# MCXN947_cm33_core0 register map
Vendor: nxp.com; File version: 1.0
CPU: CM33 r2p0, little endian, MPU, FPU, VTOR, 3 interrupt priority bits
Registers are 32-bit, read-write, reset 0x0 unless marked. A register's access mark holds for its fields unless they carry their own. Offsets are from the block's base; [hi:lo] are bit positions; {n}, {i} and the like mark numbered series; 'fields as' and 'values as' point back to an identical list.

## INPUTMUX0 (part 2 of 2) — INPUTMUX
Base 0x40006000
{0x580+4i} OPAMP{i}_TRIG reset 0x3F (i=0..2) — OPAMP{i} Trigger Input Connections
  [5:0] INP — OPAMP trigger input connections
    {v}=PINT PIN_INT{v} input is selected (v=0..3); {v}=SCT_OUT{v} input is selected (v=4..8); {v}=CTIMER{v-9}_MAT3 input is selected (v=9..13); 14=PINT GPIO_INT_BMAT input is selected; {v}=ADC0_tcomp[{v-15}] input is selected (v=15..18); {v}=ADC1_tcomp[{v-19}] input is selected (v=19..22); 23=PWM0_A0_TRIG0 input is selected; 24=PWM0_A0_TRIG1 input is selected; 25=PWM0_A1_TRIG0 input is selected; 26=PWM0_A1_TRIG1 input is selected; 27=PWM0_A2_TRIG0 input is selected; 28=PWM0_A2_TRIG1 input is selected; 29=PWM0_A3_TRIG0 input is selected; 30=PWM0_A3_TRIG1 input is selected; 31=PWM1_A0_TRIG0 input is selected; 32=PWM1_A0_TRIG1 input is selected; 33=PWM1_A1_TRIG0 input is selected; 34=PWM1_A1_TRIG1 input is selected; 35=PWM1_A2_TRIG0 input is selected; 36=PWM1_A2_TRIG1 input is selected; 37=PWM1_A3_TRIG0 input is selected; 38=PWM1_A3_TRIG1 input is selected; 39=EVTG_OUT0A input is selected; 40=EVTG_OUT0B input is selected; 41=EVTG_OUT1A input is selected; 42=EVTG_OUT1B input is selected; 43=EVTG_OUT2A input is selected; 44=EVTG_OUT2B input is selected; 45=EVTG_OUT3A input is selected; 46=EVTG_OUT3B input is selected; {v}=TRIG_IN{v-47} input is selected (v=47..50); {v}=FlexIO CH{v-47} input is selected (v=51..54)
0x5A0 FLEXCOMM0_TRIG reset 0x3F — LP_FLEXCOMM0 Trigger Input Connections
  [5:0] INP — FLEXCOMM0 trigger input connections
    0=PINT PIN_INT4 input is selected; 1=PINT PIN_INT5 input is selected; 2=PINT PIN_INT6 input is selected; 3=SCT_OUT5 input is selected; 4=SCT_OUT6 input is selected; 5=SCT_OUT7 input is selected; 6=CTIMER0_MAT1 input is selected; 7=CTIMER1_MAT1 input is selected; 8=CTIMER2_MAT0 input is selected; 9=CTIMER3_MAT0 input is selected; 10=CTIMER4_MAT0 input is selected; 11=LPTMR0 input is selected; 12=LPTMR1 input is selected; 13=ARM_TXEV input is selected; 14=PINT GPIO_INT_BMAT input is selected; 15=CMP0_OUT input is selected; 16=CMP1_OUT input is selected; 17=CMP2_OUT input is selected; 18=EVTG_OUT0A input is selected; 19=EVTG_OUT0B input is selected; 20=EVTG_OUT1A input is selected; 21=EVTG_OUT1B input is selected; 22=EVTG_OUT2A input is selected; 23=EVTG_OUT2B input is selected; 24=EVTG_OUT3A input is selected; 25=EVTG_OUT3B input is selected; {v}=TRIG_IN{v-26} input is selected (v=26..30); 31=TRIG_IN10 input is selected; 32=TRIG_IN11 input is selected; {v}=FlexIO CH{v-29} input is selected (v=33..36); 37=USB0 ipp_ind_uart_rxd_usbmux input is selected; 38=GPIO2 Pin Event Trig 0 input is selected; 39=GPIO2 Pin Event Trig 1 input is selected; 40=GPIO3 Pin Event Trig 0 input is selected; 41=GPIO3 Pin Event Trig 1 input is selected; 42=WUU input is selected
0x5C0 FLEXCOMM1_TRIG reset 0x3F — LP_FLEXCOMM1 Trigger Input Connections
  [5:0] INP — FLEXCOMM1 trigger input connections
    values as FLEXCOMM0_TRIG.INP
0x5E0 FLEXCOMM2_TRIG reset 0x3F — LP_FLEXCOMM2 Trigger Input Connections
  [5:0] INP — FLEXCOMM2 trigger input connections
    0=PINT PIN_INT4 input is selected; 1=PINT PIN_INT6 input is selected; 2=PINT PIN_INT7 input is selected; 3=SCT_OUT5 input is selected; 4=SCT_OUT8 input is selected; 5=SCT_OUT9 input is selected; {v}=CTIMER{v-6}_MAT1 input is selected (v=6..10); 11=LPTMR0 input is selected; 12=LPTMR1 input is selected; 13=ARM_TXEV input is selected; 14=PINT GPIO_INT_BMAT input is selected; 15=CMP0_OUT input is selected; 16=CMP1_OUT input is selected; 17=CMP2_OUT input is selected; 18=EVTG_OUT0A input is selected; 19=EVTG_OUT0B input is selected; 20=EVTG_OUT1A input is selected; 21=EVTG_OUT1B input is selected; 22=EVTG_OUT2A input is selected; 23=EVTG_OUT2B input is selected; 24=EVTG_OUT3A input is selected; 25=EVTG_OUT3B input is selected; {v}=TRIG_IN{v-26} input is selected (v=26..30); 31=TRIG_IN10 input is selected; 32=TRIG_IN11 input is selected; {v}=FlexIO CH{v-29} input is selected (v=33..36); 37=USB0 ipp_ind_uart_rxd_usbmux input is selected; 38=GPIO2 Pin Event Trig 0 input is selected; 39=GPIO2 Pin Event Trig 1 input is selected; 40=GPIO3 Pin Event Trig 0 input is selected; 41=GPIO3 Pin Event Trig 1 input is selected; 42=WUU input is selected
0x600 FLEXCOMM3_TRIG reset 0x3F — LP_FLEXCOMM3 Trigger Input Connections
  [5:0] INP — FLEXCOMM3 trigger input connections
    0=PINT PIN_INT4 input is selected; 1=PINT PIN_INT5 input is selected; 2=PINT PIN_INT7 input is selected; 3=SCT_OUT5 input is selected; 4=SCT_OUT8 input is selected; 5=SCT_OUT9 input is selected; {v}=CTIMER{v-6}_MAT1 input is selected (v=6..10); 11=LPTMR0 input is selected; 12=LPTMR1 input is selected; 13=ARM_TXEV input is selected; 14=PINT GPIO_INT_BMAT input is selected; 15=CMP0_OUT input is selected; 16=CMP1_OUT input is selected; 17=CMP2_OUT input is selected; 18=EVTG_OUT0A input is selected; 19=EVTG_OUT0B input is selected; 20=EVTG_OUT1A input is selected; 21=EVTG_OUT1B input is selected; 22=EVTG_OUT2A input is selected; 23=EVTG_OUT2B input is selected; 24=EVTG_OUT3A input is selected; 25=EVTG_OUT3B input is selected; {v}=TRIG_IN{v-26} input is selected (v=26..30); 31=TRIG_IN10 input is selected; 32=TRIG_IN11 input is selected; {v}=FlexIO CH{v-29} input is selected (v=33..36); 37=USB0 ipp_ind_uart_rxd_usbmux input is selected; 38=GPIO2 Pin Event Trig 0 input is selected; 39=GPIO2 Pin Event Trig 1 input is selected; 40=GPIO3 Pin Event Trig 0 input is selected; 41=GPIO3 Pin Event Trig 1 input is selected; 42=WUU input is selected
0x620 FLEXCOMM4_TRIG reset 0x3F — LP_FLEXCOMM4 Trigger Input Connections
  [5:0] INP — FLEXCOMM4 trigger input connections
    0=PINT PIN_INT4 input is selected; 1=PINT PIN_INT5 input is selected; 2=PINT PIN_INT7 input is selected; 3=SCT_OUT0 input is selected; 4=SCT_OUT1 input is selected; 5=SCT_OUT2 input is selected; 6=CTIMER0_MAT1 input is selected; 7=CTIMER1_MAT1 input is selected; 8=CTIMER2_MAT2 input is selected; 9=CTIMER3_MAT2 input is selected; 10=CTIMER4_MAT2 input is selected; 11=LPTMR0 input is selected; 12=LPTMR1 input is selected; 13=ARM_TXEV input is selected; 14=PINT GPIO_INT_BMAT input is selected; 15=CMP0_OUT input is selected; 16=CMP1_OUT input is selected; 17=CMP2_OUT input is selected; 18=EVTG_OUT0A input is selected; 19=EVTG_OUT0B input is selected; 20=EVTG_OUT1A input is selected; 21=EVTG_OUT1B input is selected; 22=EVTG_OUT2A input is selected; 23=EVTG_OUT2B input is selected; 24=EVTG_OUT3A input is selected; 25=EVTG_OUT3B input is selected; {v}=TRIG_IN{v-26} input is selected (v=26..30); 31=TRIG_IN10 input is selected; 32=TRIG_IN11 input is selected; {v}=FlexIO CH{v-29} input is selected (v=33..36); 37=USB0 ipp_ind_uart_rxd_usbmux input is selected; 38=GPIO2 Pin Event Trig 0 input is selected; 39=GPIO2 Pin Event Trig 1 input is selected; 40=GPIO3 Pin Event Trig 0 input is selected; 41=GPIO3 Pin Event Trig 1 input is selected; 42=WUU input is selected
0x640 FLEXCOMM5_TRIG reset 0x3F — LP_FLEXCOMM5 Trigger Input Connections
  [5:0] INP — FLEXCOMM5 trigger input connections
    values as FLEXCOMM4_TRIG.INP
0x660 FLEXCOMM6_TRIG reset 0x3F — LP_FLEXCOMM6 Trigger Input Connections
  [5:0] INP — FLEXCOMM6 trigger input connections
    0=PINT PIN_INT4 input is selected; 1=PINT PIN_INT5 input is selected; 2=PINT PIN_INT7 input is selected; 3=SCT_OUT0 input is selected; 4=SCT_OUT3 input is selected; 5=SCT_OUT4 input is selected; 6=CTIMER0_MAT1 input is selected; 7=CTIMER1_MAT1 input is selected; 8=CTIMER2_MAT3 input is selected; 9=CTIMER3_MAT3 input is selected; 10=CTIMER4_MAT3 input is selected; 11=LPTMR0 input is selected; 12=LPTMR1 input is selected; 13=ARM_TXEV input is selected; 14=PINT GPIO_INT_BMAT input is selected; 15=CMP0_OUT input is selected; 16=CMP1_OUT input is selected; 17=CMP2_OUT input is selected; 18=EVTG_OUT0A input is selected; 19=EVTG_OUT0B input is selected; 20=EVTG_OUT1A input is selected; 21=EVTG_OUT1B input is selected; 22=EVTG_OUT2A input is selected; 23=EVTG_OUT2B input is selected; 24=EVTG_OUT3A input is selected; 25=EVTG_OUT3B input is selected; {v}=TRIG_IN{v-26} input is selected (v=26..30); 31=TRIG_IN10 input is selected; 32=TRIG_IN11 input is selected; {v}=FlexIO CH{v-29} input is selected (v=33..36); 37=USB0 ipp_ind_uart_rxd_usbmux input is selected; 38=GPIO2 Pin Event Trig 0 input is selected; 39=GPIO2 Pin Event Trig 1 input is selected; 40=GPIO3 Pin Event Trig 0 input is selected; 41=GPIO3 Pin Event Trig 1 input is selected; 42=WUU input is selected
0x680 FLEXCOMM7_TRIG reset 0x3F — LP_FLEXCOMM7 Trigger Input Connections
  [5:0] INP — FLEXCOMM7 trigger input connections
    values as FLEXCOMM6_TRIG.INP
0x6A0 FLEXCOMM8_TRIG reset 0x3F — LP_FLEXCOMM8 Trigger Input Connections
  [5:0] INP — Flexcomm8 trigger input connections
    values as FLEXCOMM6_TRIG.INP
0x6C0 FLEXCOMM9_TRIG reset 0x3F — LP_FLEXCOMM9 Trigger Input Connections
  [5:0] INP — Flexcomm9 trigger input connections
    0=PINT PIN_INT4 input is selected; 1=PINT PIN_INT5 input is selected; 2=PINT PIN_INT7 input is selected; 3=SCT_OUT0 input is selected; 4=SCT_OUT3 input is selected; 5=SCT_OUT4 input is selected; 6=CTIMER0_MAT1 input is selected; 7=CTIMER1_MAT1 input is selected; 8=CTIMER2_MAT0 input is selected; 9=CTIMER3_MAT0 input is selected; 10=CTIMER4_MAT0 input is selected; 11=LPTMR0 input is selected; 12=LPTMR1 input is selected; 13=ARM_TXEV input is selected; 14=PINT GPIO_INT_BMAT input is selected; 15=CMP0_OUT input is selected; 16=CMP1_OUT input is selected; 17=CMP2_OUT input is selected; 18=EVTG_OUT0A input is selected; 19=EVTG_OUT0B input is selected; 20=EVTG_OUT1A input is selected; 21=EVTG_OUT1B input is selected; 22=EVTG_OUT2A input is selected; 23=EVTG_OUT2B input is selected; 24=EVTG_OUT3A input is selected; 25=EVTG_OUT3B input is selected; {v}=TRIG_IN{v-26} input is selected (v=26..30); 31=TRIG_IN10 input is selected; 32=TRIG_IN11 input is selected; {v}=FlexIO CH{v-29} input is selected (v=33..36); 37=USB0 ipp_ind_uart_rxd_usbmux input is selected; 38=GPIO2 Pin Event Trig 0 input is selected; 39=GPIO2 Pin Event Trig 1 input is selected; 40=GPIO3 Pin Event Trig 0 input is selected; 41=GPIO3 Pin Event Trig 1 input is selected; 42=WUU input is selected
{0x6E0+4i} FLEXIO_TRIG{i} reset 0x7F (i=0..7) — FlexIO Trigger Input Connections {i}
  [6:0] INP — Input number for FlexIO0.
    {v}=PINT PIN_INT{v+4} input is selected (v=0..3); {v}=SCT_OUT{v+1} input is selected (v=4..8); {v}=T{v-9}_MAT1 input is selected (v=9..13); 14=LPTMR0 input is selected; 15=LPTMR1 input is selected; 16=ARM_TXEV input is selected; 17=PINT GPIO_INT_BMAT input is selected; {v}=ADC0_tcomp[{v-18}] input is selected (v=18..21); {v}=ADC1_tcomp[{v-22}] input is selected (v=22..25); 26=CMP0_OUT input is selected; 27=CMP1_OUT input is selected; 28=CMP2_OUT input is selected; 29=PWM0_A0_TRIG0 input is selected; 30=PWM0_A0_TRIG1 input is selected; 31=PWM0_A1_TRIG0 input is selected; 32=PWM0_A1_TRIG1 input is selected; 33=PWM0_A2_TRIG0 input is selected; 34=PWM0_A2_TRIG1 input is selected; 35=PWM0_A3_TRIG0 input is selected; 36=PWM0_A3_TRIG1 input is selected; 37=PWM1_A0_TRIG0 input is selected; 38=PWM1_A0_TRIG1 input is selected; 39=PWM1_A1_TRIG0 input is selected; 40=PWM1_A1_TRIG1 input is selected; 41=PWM1_A2_TRIG0 input is selected; 42=PWM1_A2_TRIG1 input is selected; 43=PWM1_A3_TRIG0 input is selected; 44=PWM1_A3_TRIG1 input is selected; 45=EVTG_OUT0A input is selected; 46=EVTG_OUT0B input is selected; 47=EVTG_OUT1A input is selected; 48=EVTG_OUT1B input is selected; 49=EVTG_OUT2A input is selected; 50=EVTG_OUT2B input is selected; 51=EVTG_OUT3A input is selected; 52=EVTG_OUT3B input is selected; {v}=TRIG_IN{v-53} input is selected (v=53..57); {v}=SINC Filter CH{v-58} Conversion Complete input is selected (v=58..62); 63=LP_FLEXCOMM0 trig 0 (lpuart_trg_txword) input is selected; 64=LP_FLEXCOMM0 trig 1 (lpuart_trg_rxword) input is selected; 65=LP_FLEXCOMM0 trig 2 (lpuart_trg_rxidle) input is selected; 66=LP_FLEXCOMM1 trig 0 input is selected; 67=LP_FLEXCOMM1 trig 1 input is selected; 68=LP_FLEXCOMM1 trig 2 input is selected; 69=LP_FLEXCOMM2 trig 0 input is selected; 70=LP_FLEXCOMM2 trig 1 input is selected; 71=LP_FLEXCOMM2 trig 2 input is selected; {v}=LP_FLEXCOMM3 trig {v-72} input is selected (v=72..75); 76=WUU input is selected
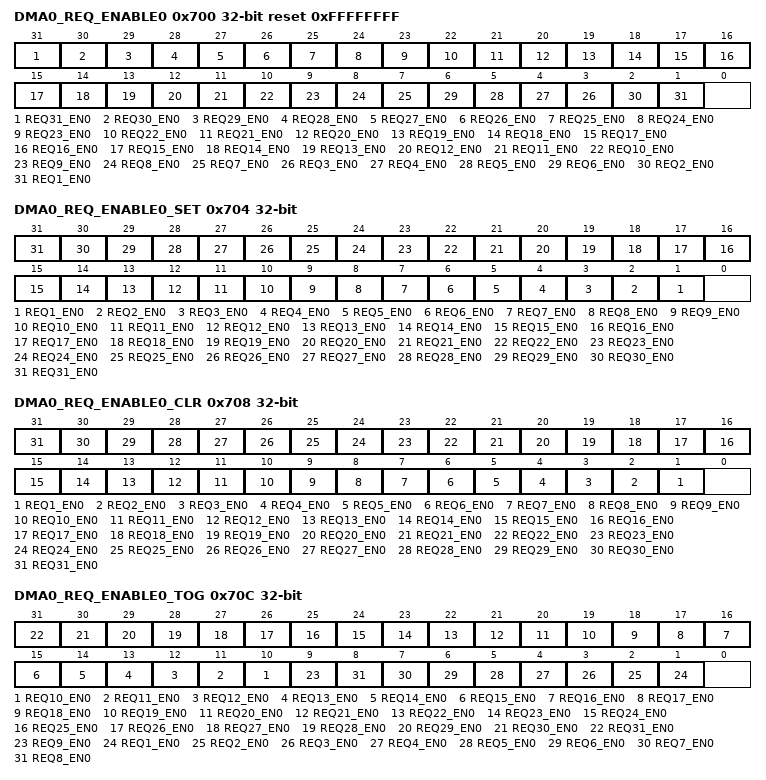
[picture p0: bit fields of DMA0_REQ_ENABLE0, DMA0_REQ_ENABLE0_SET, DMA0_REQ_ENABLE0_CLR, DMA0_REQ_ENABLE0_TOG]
0x700 DMA0_REQ_ENABLE0 reset 0xFFFFFFFF — DMA0 Request Enable0
  [all] fields
    0=Disable; 1=Enable
  [31] REQ31_EN0 — This register is used to enable and disable OUT0A request.
  [30] REQ30_EN0 — This register is used to enable and disable DMA_request.
  [29] REQ29_EN0 — This register is used to enable and disable DMA_request.
  [28] REQ28_EN0 — This register is used to enable and disable DMA_request.
  [27] REQ27_EN0 — This register is used to enable and disable FIFO_request.
  [26] REQ26_EN0 — This register is used to enable and disable FIFO_request.
  [25] REQ25_EN0 — This register is used to enable and disable FIFO_request.
  [24] REQ24_EN0 — This register is used to enable and disable FIFO B request.
  [23] REQ23_EN0 — This register is used to enable and disable FIFO A request.
  [22] REQ22_EN0 — This register is used to enable and disable FIFO B request.
  [21] REQ21_EN0 — This register is used to enable and disable FIFO A request.
  [20] REQ20_EN0 — This register is used to enable and disable DMA1 request.
  [19] REQ19_EN0 — This register is used to enable and disable DMA0 request.
  [18] REQ18_EN0 — This register is used to enable and disable FIFO_request.
  [17] REQ17_EN0 — This register is used to enable and disable wake up event request.
  [16] REQ16_EN0 — This register is used to enable and disable DMAREQ_M1 request.
  [15] REQ15_EN0 — This register is used to enable and disable DMAREQ_M0 request.
  [14] REQ14_EN0 — This register is used to enable and disable DMAREQ_M1 request.
  [13] REQ13_EN0 — This register is used to enable and disable DMAREQ_M0 request.
  [12] REQ12_EN0 — This register is used to enable and disable DMAREQ_M1 request.
  [11] REQ11_EN0 — This register is used to enable and disable DMAREQ_M0 request.
  [10] REQ10_EN0 — This register is used to enable and disable DMAREQ_M1 request.
  [9] REQ9_EN0 — This register is used to enable and disable DMAREQ_M0 request.
  [8] REQ8_EN0 — This register is used to enable and disable DMAREQ_M1 request.
  [7] REQ7_EN0 — This register is used to enable and disable DMAREQ_M0 request.
  [n] REQ{n}_EN0 (n=3..6) — This register is used to enable and disable INT{n-3} request.
  [2] REQ2_EN0 — This register is used to enable and disable FLEXSPI0 transmit event request.
  [1] REQ1_EN0 — This register is used to enable and disable FLEXSPI0 receive event request.
0x704 DMA0_REQ_ENABLE0_SET wo — DMA0 Request Enable0
  [n] REQ{n}_EN0 (n=1..31) — Writing a 1 to REQ{n}_EN0 in this register sets the corresponding bit in DMA0_REQ_ENABLE0.
0x708 DMA0_REQ_ENABLE0_CLR wo — DMA0 Request Enable0
  [n] REQ{n}_EN0 (n=1..31) — Writing a 1 to REQ{n}_EN0 in this register clears the corresponding bit in DMA0_REQ_ENABLE0.
0x70C DMA0_REQ_ENABLE0_TOG wo — DMA0 Request Enable0
  [n] REQ{n}_EN0 (n=10..31) — Writing a 1 to REQ{n}_EN0 in this register toggles the corresponding bit in DMA0_REQ_ENABLE0.
  [9] REQ9_EN0 — Writing a 1 to RE9_EN0 in this register toggles the corresponding bit in DMA0_REQ_ENABLE0.
  [n] REQ{n}_EN0 (n=1..8) — Writing a 1 to REQ{n}_EN0 in this register toggles the corresponding bit in DMA0_REQ_ENABLE0.
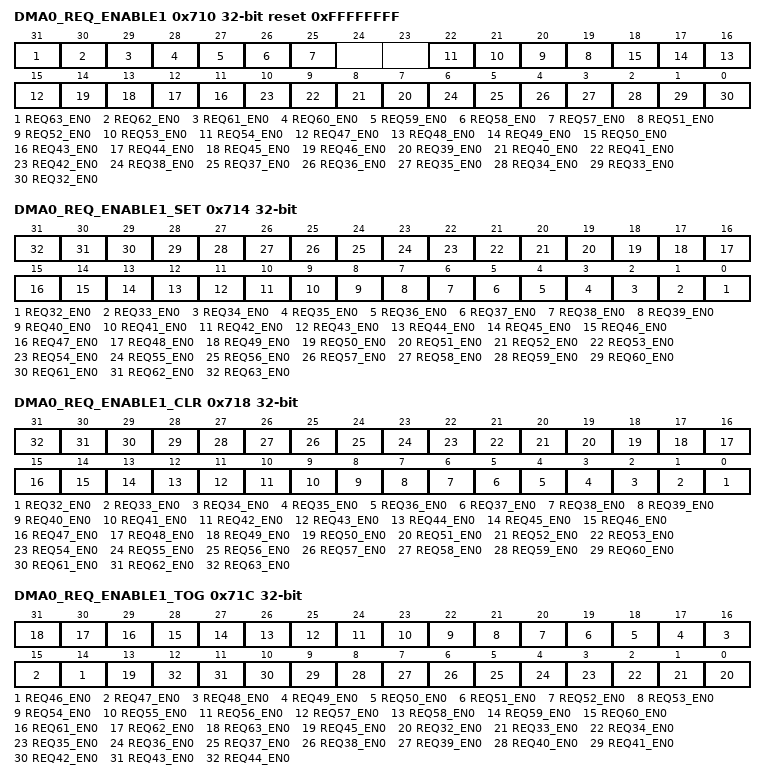
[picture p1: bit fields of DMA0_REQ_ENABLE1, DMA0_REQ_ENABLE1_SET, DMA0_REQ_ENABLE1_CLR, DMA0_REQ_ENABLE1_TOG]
0x710 DMA0_REQ_ENABLE1 reset 0xFFFFFFFF — DMA0 Request Enable1
  [all] fields
    0=Disable; 1=Enable
  [31] REQ63_EN0 — This register is used to enable and disable shift register 2 request.
  [30] REQ62_EN0 — This register is used to enable and disable shift register 1 request.
  [29] REQ61_EN0 — This register is used to enable and disable shift register 0 request.
  [28] REQ60_EN0 — This register is used to enable and disable DMA request.
  [27] REQ59_EN0 — This register is used to enable and disable DMA request.
  [26] REQ58_EN0 — This register is used to enable and disable counter match event request.
  [25] REQ57_EN0 — This register is used to enable and disable counter match event request.
  [n-32] REQ{n}_EN0 (n=51..54) — This register is used to enable and disable Req_val{n-51} request.
  [n-32] REQ{n}_EN0 (n=47..50) — This register is used to enable and disable Req_capt{n-47} request.
  [n-32] REQ{n}_EN0 (n=43..46) — This register is used to enable and disable Req_val{n-43} request.
  [n-32] REQ{n}_EN0 (n=39..42) — This register is used to enable and disable Req_capt{n-39} request.
  [6] REQ38_EN0 — This register is used to enable and disable OUT3B request.
  [5] REQ37_EN0 — This register is used to enable and disable OUT3A request.
  [4] REQ36_EN0 — This register is used to enable and disable OUT2B request.
  [3] REQ35_EN0 — This register is used to enable and disable OUT2A request.
  [2] REQ34_EN0 — This register is used to enable and disable OUT1B request.
  [1] REQ33_EN0 — This register is used to enable and disable OUT1A request.
  [0] REQ32_EN0 — This register is used to enable and disable OUT0B request.
0x714 DMA0_REQ_ENABLE1_SET wo — DMA0 Request Enable1
  [n-32] REQ{n}_EN0 (n=32..63) — Writing a 1 to REQ{n}_EN0 in this register sets the corresponding bit in DMA0_REQ_ENABLE1.
0x718 DMA0_REQ_ENABLE1_CLR wo — DMA0 Request Enable1
  [n-32] REQ{n}_EN0 (n=32..63) — Writing a 1 to REQ{n}_EN0 in this register clears the corresponding bit in DMA0_REQ_ENABLE1.
0x71C DMA0_REQ_ENABLE1_TOG wo — DMA0 Request Enable1
  [n-32] REQ{n}_EN0 (n=46..63) — Writing a 1 to REQ{n}_EN0 in this register toggles the corresponding bit in DMA0_REQ_ENABLE1.
  [13] REQ45_EN0 — Writing a 1 to REQ55_EN0 in this register toggles the corresponding bit in DMA0_REQ_ENABLE1.
  [n-32] REQ{n}_EN0 (n=32..44) — Writing a 1 to REQ{n}_EN0 in this register toggles the corresponding bit in DMA0_REQ_ENABLE1.
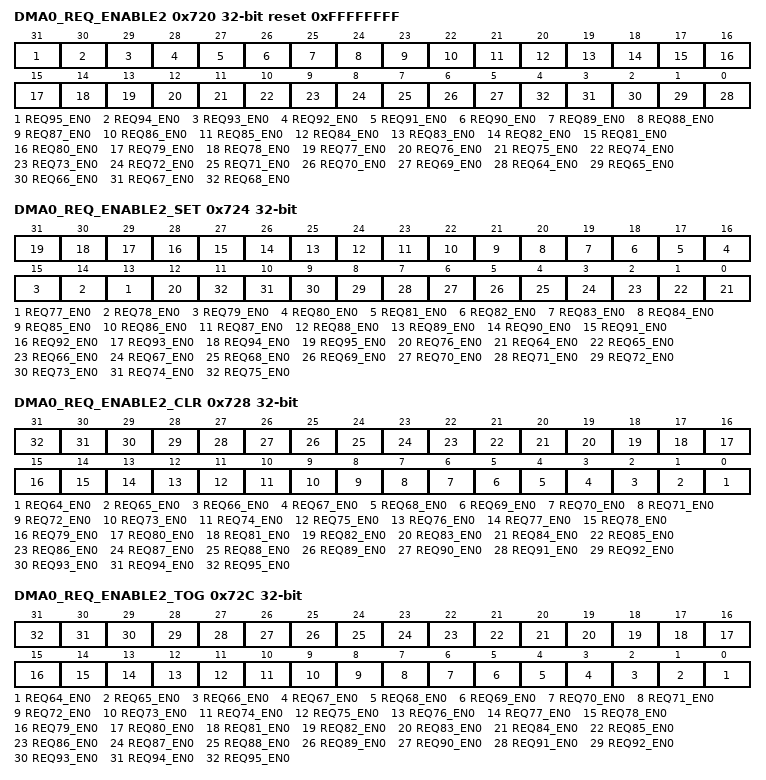
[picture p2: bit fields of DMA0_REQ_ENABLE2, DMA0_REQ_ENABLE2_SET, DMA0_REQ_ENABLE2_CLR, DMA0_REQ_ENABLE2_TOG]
0x720 DMA0_REQ_ENABLE2 reset 0xFFFFFFFF — DMA0 Request Enable2
  [all] fields
    0=Disable; 1=Enable
  [31] REQ95_EN0 — This register is used to enable and disable receive request.
  [30] REQ94_EN0 — This register is used to enable and disable transmit request.
  [29] REQ93_EN0 — This register is used to enable and disable receive request.
  [28] REQ92_EN0 — This register is used to enable and disable transmit request.
  [27] REQ91_EN0 — This register is used to enable and disable receive request.
  [26] REQ90_EN0 — This register is used to enable and disable channel 1 request.
  [25] REQ89_EN0 — This register is used to enable and disable channel 0 request.
  [24] REQ88_EN0 — This register is used to enable and disable transmit request.
  [23] REQ87_EN0 — This register is used to enable and disable receive request.
  [22] REQ86_EN0 — This register is used to enable and disable transmit request.
  [21] REQ85_EN0 — This register is used to enable and disable receive request.
  [20] REQ84_EN0 — This register is used to enable and disable transmit request.
  [19] REQ83_EN0 — This register is used to enable and disable receive request.
  [18] REQ82_EN0 — This register is used to enable and disable transmit request.
  [17] REQ81_EN0 — This register is used to enable and disable receive request.
  [16] REQ80_EN0 — This register is used to enable and disable transmit request.
  [15] REQ79_EN0 — This register is used to enable and disable receive request.
  [14] REQ78_EN0 — This register is used to enable and disable transmit request.
  [13] REQ77_EN0 — This register is used to enable and disable receive request.
  [12] REQ76_EN0 — This register is used to enable and disable transmit request.
  [11] REQ75_EN0 — This register is used to enable and disable receive request.
  [10] REQ74_EN0 — This register is used to enable and disable transmit request.
  [9] REQ73_EN0 — This register is used to enable and disable receive request.
  [8] REQ72_EN0 — This register is used to enable and disable transmit request.
  [7] REQ71_EN0 — This register is used to enable and disable receive request.
  [6] REQ70_EN0 — This register is used to enable and disable transmit request.
  [5] REQ69_EN0 — This register is used to enable and disable receive request.
  [n-64] REQ{n}_EN0 (n=64..68) — This register is used to enable and disable shift register {n-61} request.
0x724 DMA0_REQ_ENABLE2_SET wo — DMA0 Request Enable2
  [n-64] REQ{n}_EN0 (n=77..95) — Writing a 1 to REQ{n}_EN0 in this register sets the corresponding bit in DMA0_REQ_ENABLE2.
  [12] REQ76_EN0 — Writing a 1 to REQ876_EN0 in this register sets the corresponding bit in DMA0_REQ_ENABLE2.
  [n-64] REQ{n}_EN0 (n=64..75) — Writing a 1 to REQ{n}_EN0 in this register sets the corresponding bit in DMA0_REQ_ENABLE2.
0x728 DMA0_REQ_ENABLE2_CLR wo — DMA0 Request Enable2
  [n-64] REQ{n}_EN0 (n=64..95) — Writing a 1 to REQ{n}_EN0 in this register clears the corresponding bit in DMA0_REQ_ENABLE2.
0x72C DMA0_REQ_ENABLE2_TOG wo — DMA0 Request Enable2
  [n-64] REQ{n}_EN0 (n=64..95) — Writing a 1 to REQ{n}_EN0 in this register toggles the corresponding bit in DMA0_REQ_ENABLE2.
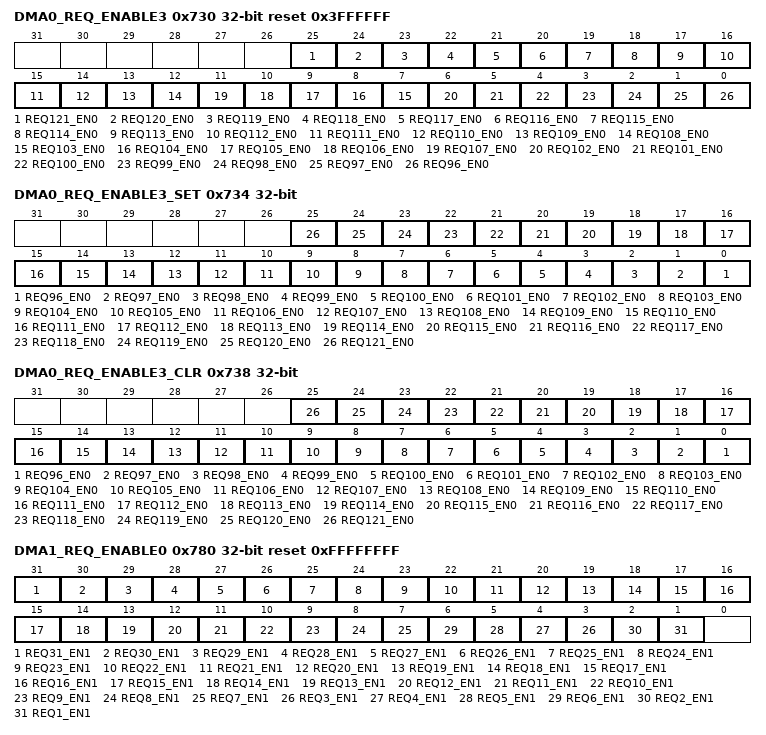
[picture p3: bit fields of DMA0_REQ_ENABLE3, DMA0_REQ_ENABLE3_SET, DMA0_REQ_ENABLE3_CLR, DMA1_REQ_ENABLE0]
0x730 DMA0_REQ_ENABLE3 reset 0x3FFFFFF — DMA0 Request Enable3
  [all] fields
    0=Disable; 1=Enable
  [25] REQ121_EN0 — This register is used to enable and disable out of range request.
  [24] REQ120_EN0 — This register is used to enable and disable end of scan request.
  [23] REQ119_EN0 — This register is used to enable and disable pin event request 1.
  [22] REQ118_EN0 — This register is used to enable and disable pin event request 0.
  [21] REQ117_EN0 — This register is used to enable and disable pin event request 1.
  [20] REQ116_EN0 — This register is used to enable and disable pin event request 0.
  [19] REQ115_EN0 — This register is used to enable and disable pin event request 1.
  [18] REQ114_EN0 — This register is used to enable and disable pin event request 0.
  [17] REQ113_EN0 — This register is used to enable and disable pin event request 1.
  [16] REQ112_EN0 — This register is used to enable and disable pin event request 0.
  [15] REQ111_EN0 — This register is used to enable and disable pin event request 1.
  [14] REQ110_EN0 — This register is used to enable and disable pin event request 0.
  [13] REQ109_EN0 — This register is used to enable and disable pin event request 1.
  [12] REQ108_EN0 — This register is used to enable and disable pin event request 0.
  [n-96] REQ{n}_EN0 (n=103..107) — This register is used to enable and disable ipd_req_sinc[{n-103}] or ipd_req_alt [{n-103}] request.
  [6] REQ102_EN0 — This register is used to enable and disable transmit request.
  [5] REQ101_EN0 — This register is used to enable and disable receive request.
  [4] REQ100_EN0 — This register is used to enable and disable transmit request.
  [3] REQ99_EN0 — This register is used to enable and disable shift register 6 request.
  [2] REQ98_EN0 — This register is used to enable and disable transmit request.
  [1] REQ97_EN0 — This register is used to enable and disable shift register 4 request.
  [0] REQ96_EN0 — This register is used to enable and disable transmit request.
0x734 DMA0_REQ_ENABLE3_SET wo — DMA0 Request Enable3
  [n-96] REQ{n}_EN0 (n=96..121) — Writing a 1 to REQ{n}_EN0 in this register sets the corresponding bit in DMA0_REQ_ENABLE3
0x738 DMA0_REQ_ENABLE3_CLR wo — DMA0 Request Enable3
  [n-96] REQ{n}_EN0 (n=96..121) — Writing a 1 to REQ{n}_EN0 in this register clears the corresponding bit in DMA0_REQ_ENABLE3
0x780 DMA1_REQ_ENABLE0 reset 0xFFFFFFFF — DMA1 Request Enable0
  [all] fields
    0=Disable; 1=Enable
  [31] REQ31_EN1 — This register is used to enable and disable OUT0A request.
  [30] REQ30_EN1 — This register is used to enable and disable DMA_request.
  [29] REQ29_EN1 — This register is used to enable and disable DMA_request.
  [28] REQ28_EN1 — This register is used to enable and disable DMA_request.
  [27] REQ27_EN1 — This register is used to enable and disable FIFO_request.
  [26] REQ26_EN1 — This register is used to enable and disable FIFO_request.
  [25] REQ25_EN1 — This register is used to enable and disable FIFO_request.
  [24] REQ24_EN1 — This register is used to enable and disable FIFO B request.
  [23] REQ23_EN1 — This register is used to enable and disable FIFO A request.
  [22] REQ22_EN1 — This register is used to enable and disable FIFO B request.
  [21] REQ21_EN1 — This register is used to enable and disable FIFO A request.
  [20] REQ20_EN1 — This register is used to enable and disable DMA1 request.
  [19] REQ19_EN1 — This register is used to enable and disable DMA0 request.
  [18] REQ18_EN1 — This register is used to enable and disable FIFO_request.
  [17] REQ17_EN1 — This register is used to enable and disable wake up event request.
  [16] REQ16_EN1 — This register is used to enable and disable DMAREQ_M1 request.
  [15] REQ15_EN1 — This register is used to enable and disable DMAREQ_M0 request.
  [14] REQ14_EN1 — This register is used to enable and disable DMAREQ_M1 request.
  [13] REQ13_EN1 — This register is used to enable and disable DMAREQ_M0 request.
  [12] REQ12_EN1 — This register is used to enable and disable DMAREQ_M1 request.
  [11] REQ11_EN1 — This register is used to enable and disable DMAREQ_M0 request.
  [10] REQ10_EN1 — This register is used to enable and disable DMAREQ_M1 request.
  [9] REQ9_EN1 — This register is used to enable and disable DMAREQ_M0 request.
  [8] REQ8_EN1 — This register is used to enable and disable DMAREQ_M1 request.
  [7] REQ7_EN1 — This register is used to enable and disable DMAREQ_M0 request.
  [n] REQ{n}_EN1 (n=3..6) — This register is used to enable and disable INT{n-3} request.
  [2] REQ2_EN1 — This register is used to enable and disable FLEXSPI0 transmit event request.
  [1] REQ1_EN1 — This register is used to enable and disable FLEXSPI0 receive event request.
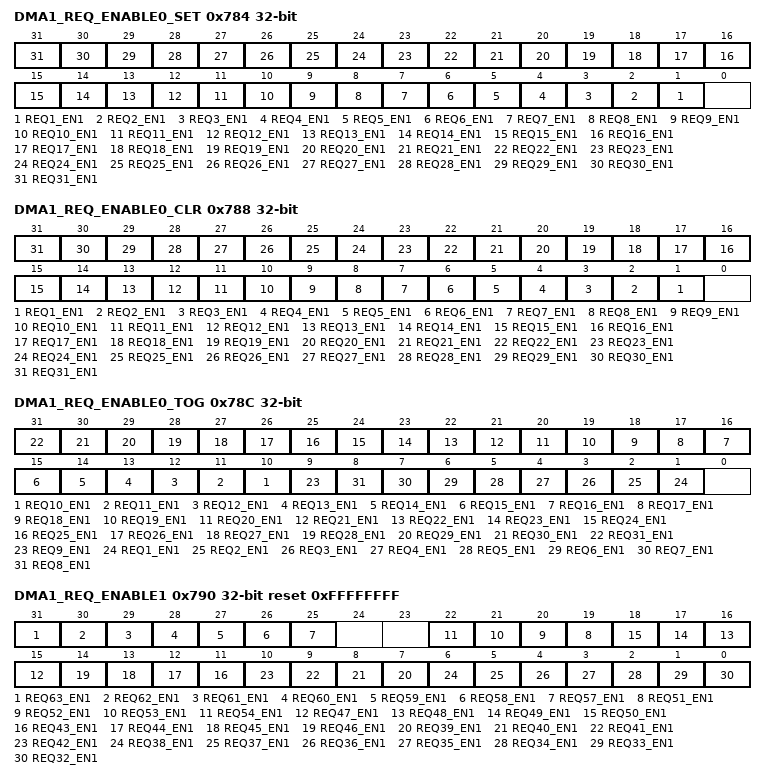
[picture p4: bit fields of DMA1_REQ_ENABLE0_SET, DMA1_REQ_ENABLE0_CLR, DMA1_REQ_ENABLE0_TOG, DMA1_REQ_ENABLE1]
0x784 DMA1_REQ_ENABLE0_SET wo — DMA1 Request Enable0
  [n] REQ{n}_EN1 (n=1..31) — Writing a 1 to REQ{n}_EN1 in this register sets the corresponding bit in DMA1_REQ_ENABLE0.
0x788 DMA1_REQ_ENABLE0_CLR wo — DMA1 Request Enable0
  [n] REQ{n}_EN1 (n=1..31) — Writing a 1 to REQ{n}_EN1 in this register clears the corresponding bit in DMA1_REQ_ENABLE0.
0x78C DMA1_REQ_ENABLE0_TOG wo — DMA1 Request Enable0
  [n] REQ{n}_EN1 (n=10..31) — Writing a 1 to REQ{n}_EN1 in this register toggles the corresponding bit in DMA1_REQ_ENABLE0.
  [9] REQ9_EN1 — Writing a 1 to RE9_EN1 in this register toggles the corresponding bit in DMA1_REQ_ENABLE0.
  [n] REQ{n}_EN1 (n=1..8) — Writing a 1 to REQ{n}_EN1 in this register toggles the corresponding bit in DMA1_REQ_ENABLE0.
0x790 DMA1_REQ_ENABLE1 reset 0xFFFFFFFF — DMA1 Request Enable1
  [all] fields
    0=Disable; 1=Enable
  [31] REQ63_EN1 — This register is used to enable and disable shift register 2 request.
  [30] REQ62_EN1 — This register is used to enable and disable shift register 1 request.
  [29] REQ61_EN1 — This register is used to enable and disable shift register 0 request.
  [28] REQ60_EN1 — This register is used to enable and disable DMA request.
  [27] REQ59_EN1 — This register is used to enable and disable DMA request.
  [26] REQ58_EN1 — This register is used to enable and disable counter match event request.
  [25] REQ57_EN1 — This register is used to enable and disable counter match event request.
  [n-32] REQ{n}_EN1 (n=51..54) — This register is used to enable and disable Req_val{n-51} request.
  [n-32] REQ{n}_EN1 (n=47..50) — This register is used to enable and disable Req_capt{n-47} request.
  [n-32] REQ{n}_EN1 (n=43..46) — This register is used to enable and disable Req_val{n-43} request.
  [n-32] REQ{n}_EN1 (n=39..42) — This register is used to enable and disable Req_capt{n-39} request.
  [6] REQ38_EN1 — This register is used to enable and disable OUT3B request.
  [5] REQ37_EN1 — This register is used to enable and disable OUT3A request.
  [4] REQ36_EN1 — This register is used to enable and disable OUT2B request.
  [3] REQ35_EN1 — This register is used to enable and disable OUT2A request.
  [2] REQ34_EN1 — This register is used to enable and disable OUT1B request.
  [1] REQ33_EN1 — This register is used to enable and disable OUT1A request.
  [0] REQ32_EN1 — This register is used to enable and disable OUT0B request.
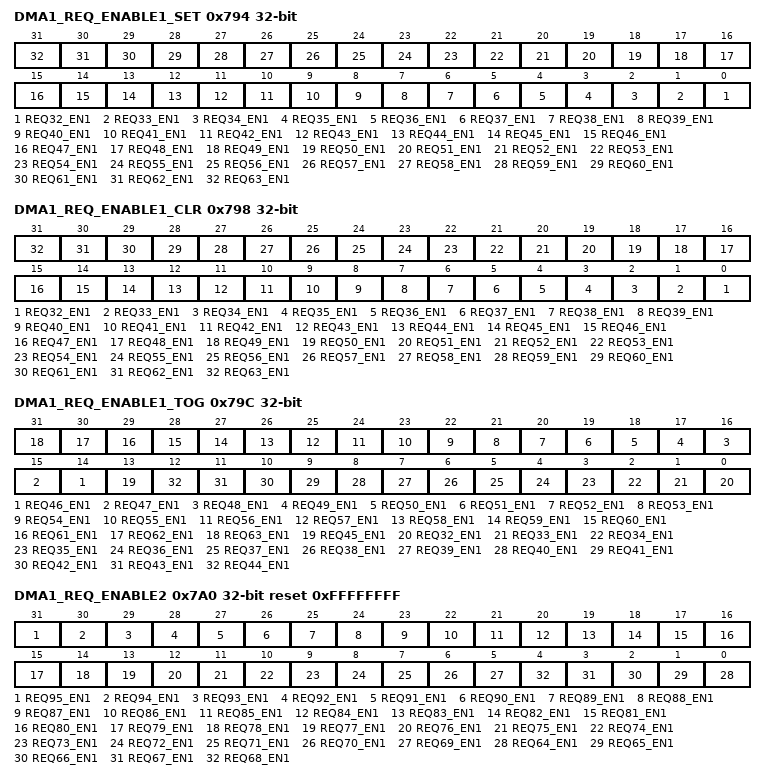
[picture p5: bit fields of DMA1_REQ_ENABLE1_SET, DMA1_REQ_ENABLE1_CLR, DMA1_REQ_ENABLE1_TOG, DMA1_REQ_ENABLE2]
0x794 DMA1_REQ_ENABLE1_SET wo — DMA1 Request Enable1
  [n-32] REQ{n}_EN1 (n=32..63) — Writing a 1 to REQ{n}_EN1 in this register sets the corresponding bit in DMA1_REQ_ENABLE1.
0x798 DMA1_REQ_ENABLE1_CLR wo — DMA1 Request Enable1
  [n-32] REQ{n}_EN1 (n=32..63) — Writing a 1 to REQ{n}_EN1 in this register clears the corresponding bit in DMA1_REQ_ENABLE1.
0x79C DMA1_REQ_ENABLE1_TOG wo — DMA1 Request Enable1
  [n-32] REQ{n}_EN1 (n=46..63) — Writing a 1 to REQ{n}_EN1 in this register toggles the corresponding bit in DMA1_REQ_ENABLE1.
  [13] REQ45_EN1 — Writing a 1 to REQ55_EN1 in this register toggles the corresponding bit in DMA1_REQ_ENABLE1.
  [n-32] REQ{n}_EN1 (n=32..44) — Writing a 1 to REQ{n}_EN1 in this register toggles the corresponding bit in DMA1_REQ_ENABLE1.
0x7A0 DMA1_REQ_ENABLE2 reset 0xFFFFFFFF — DMA1 Request Enable2
  [all] fields
    0=Disable; 1=Enable
  [31] REQ95_EN1 — This register is used to enable and disable receive request.
  [30] REQ94_EN1 — This register is used to enable and disable transmit request.
  [29] REQ93_EN1 — This register is used to enable and disable receive request.
  [28] REQ92_EN1 — This register is used to enable and disable transmit request.
  [27] REQ91_EN1 — This register is used to enable and disable receive request.
  [26] REQ90_EN1 — This register is used to enable and disable channel 1 request.
  [25] REQ89_EN1 — This register is used to enable and disable channel 0 request.
  [24] REQ88_EN1 — This register is used to enable and disable transmit request.
  [23] REQ87_EN1 — This register is used to enable and disable receive request.
  [22] REQ86_EN1 — This register is used to enable and disable transmit request.
  [21] REQ85_EN1 — This register is used to enable and disable receive request.
  [20] REQ84_EN1 — This register is used to enable and disable transmit request.
  [19] REQ83_EN1 — This register is used to enable and disable receive request.
  [18] REQ82_EN1 — This register is used to enable and disable transmit request.
  [17] REQ81_EN1 — This register is used to enable and disable receive request.
  [16] REQ80_EN1 — This register is used to enable and disable transmit request.
  [15] REQ79_EN1 — This register is used to enable and disable receive request.
  [14] REQ78_EN1 — This register is used to enable and disable transmit request.
  [13] REQ77_EN1 — This register is used to enable and disable receive request.
  [12] REQ76_EN1 — This register is used to enable and disable transmit request.
  [11] REQ75_EN1 — This register is used to enable and disable receive request.
  [10] REQ74_EN1 — This register is used to enable and disable transmit request.
  [9] REQ73_EN1 — This register is used to enable and disable receive request.
  [8] REQ72_EN1 — This register is used to enable and disable transmit request.
  [7] REQ71_EN1 — This register is used to enable and disable receive request.
  [6] REQ70_EN1 — This register is used to enable and disable transmit request.
  [5] REQ69_EN1 — This register is used to enable and disable receive request.
  [n-64] REQ{n}_EN1 (n=64..68) — This register is used to enable and disable shift register {n-61} request.
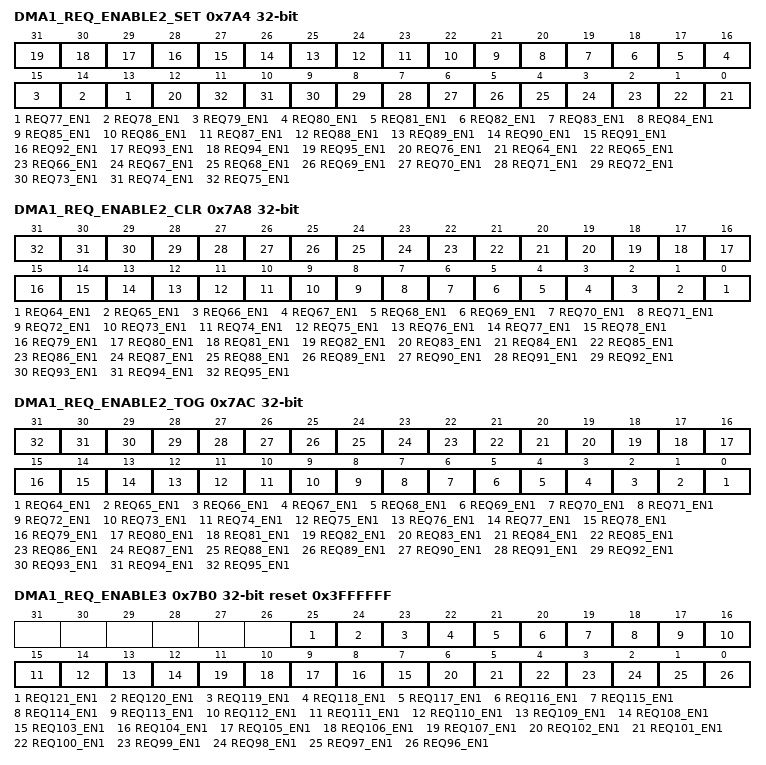
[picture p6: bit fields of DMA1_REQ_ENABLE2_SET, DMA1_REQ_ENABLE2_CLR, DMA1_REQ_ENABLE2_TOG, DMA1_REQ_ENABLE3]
0x7A4 DMA1_REQ_ENABLE2_SET wo — DMA1 Request Enable2
  [n-64] REQ{n}_EN1 (n=77..95) — Writing a 1 to REQ{n}_EN1 in this register sets the corresponding bit in DMA1_REQ_ENABLE2.
  [12] REQ76_EN1 — Writing a 1 to REQ876_EN1 in this register sets the corresponding bit in DMA1_REQ_ENABLE2.
  [n-64] REQ{n}_EN1 (n=64..75) — Writing a 1 to REQ{n}_EN1 in this register sets the corresponding bit in DMA1_REQ_ENABLE2.
0x7A8 DMA1_REQ_ENABLE2_CLR wo — DMA1 Request Enable2
  [n-64] REQ{n}_EN1 (n=64..95) — Writing a 1 to REQ{n}_EN1 in this register clears the corresponding bit in DMA1_REQ_ENABLE2.
0x7AC DMA1_REQ_ENABLE2_TOG wo — DMA1 Request Enable2
  [n-64] REQ{n}_EN1 (n=64..95) — Writing a 1 to REQ{n}_EN1 in this register toggles the corresponding bit in DMA1_REQ_ENABLE2.
0x7B0 DMA1_REQ_ENABLE3 reset 0x3FFFFFF — DMA1 Request Enable3
  [all] fields
    0=Disable; 1=Enable
  [25] REQ121_EN1 — This register is used to enable and disable out of range request.
  [24] REQ120_EN1 — This register is used to enable and disable end of scan request.
  [23] REQ119_EN1 — This register is used to enable and disable pin event request 1.
  [22] REQ118_EN1 — This register is used to enable and disable pin event request 0.
  [21] REQ117_EN1 — This register is used to enable and disable pin event request 1.
  [20] REQ116_EN1 — This register is used to enable and disable pin event request 0.
  [19] REQ115_EN1 — This register is used to enable and disable pin event request 1.
  [18] REQ114_EN1 — This register is used to enable and disable pin event request 0.
  [17] REQ113_EN1 — This register is used to enable and disable pin event request 1.
  [16] REQ112_EN1 — This register is used to enable and disable pin event request 0.
  [15] REQ111_EN1 — This register is used to enable and disable pin event request 1.
  [14] REQ110_EN1 — This register is used to enable and disable pin event request 0.
  [13] REQ109_EN1 — This register is used to enable and disable pin event request 1.
  [12] REQ108_EN1 — This register is used to enable and disable pin event request 0.
  [n-96] REQ{n}_EN1 (n=103..107) — This register is used to enable and disable ipd_req_sinc[{n-103}] or ipd_req_alt [{n-103}] request.
  [6] REQ102_EN1 — This register is used to enable and disable transmit request.
  [5] REQ101_EN1 — This register is used to enable and disable receive request.
  [4] REQ100_EN1 — This register is used to enable and disable transmit request.
  [3] REQ99_EN1 — This register is used to enable and disable shift register 6 request.
  [2] REQ98_EN1 — This register is used to enable and disable transmit request.
  [1] REQ97_EN1 — This register is used to enable and disable shift register 4 request.
  [0] REQ96_EN1 — This register is used to enable and disable transmit request.
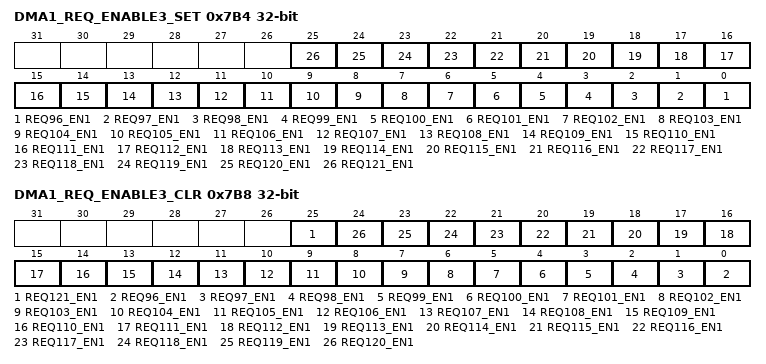
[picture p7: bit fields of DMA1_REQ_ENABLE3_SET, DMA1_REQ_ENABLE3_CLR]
0x7B4 DMA1_REQ_ENABLE3_SET wo — DMA1 Request Enable3
  [n-96] REQ{n}_EN1 (n=96..121) — Writing a 1 to REQ{n}_EN1 in this register sets the corresponding bit in DMA0_REQ_ENABLE3
0x7B8 DMA1_REQ_ENABLE3_CLR wo — DMA1 Request Enable3
  [25] REQ121_EN1 — Writing a 1 to REQ121_EN1 in this register clears the corresponding bit in DMA0_REQ_ENABLE3.
  [n-96] REQ{n}_EN1 (n=96..120) — Writing a 1 to REQ{n}_EN1 in this register clears the corresponding bit in DMA0_REQ_ENABLE3
